# MK70F12 register map
Vendor: Freescale Semiconductor, Inc.; Series: Kinetis_K; File version: 1.6
CPU: CM4 r0p1, little endian, no MPU, FPU, VTOR, 4 interrupt priority bits
Registers are 32-bit, read-write, reset 0x0 unless marked. A register's access mark holds for its fields unless they carry their own. Offsets are from the block's base; [hi:lo] are bit positions; {n}, {i} and the like mark numbered series; 'fields as' and 'values as' point back to an identical list; <NAME> marks a mode.

## ENET — Ethernet MAC-NET Core
Base 0x400C0000; register names take the prefix ENET_
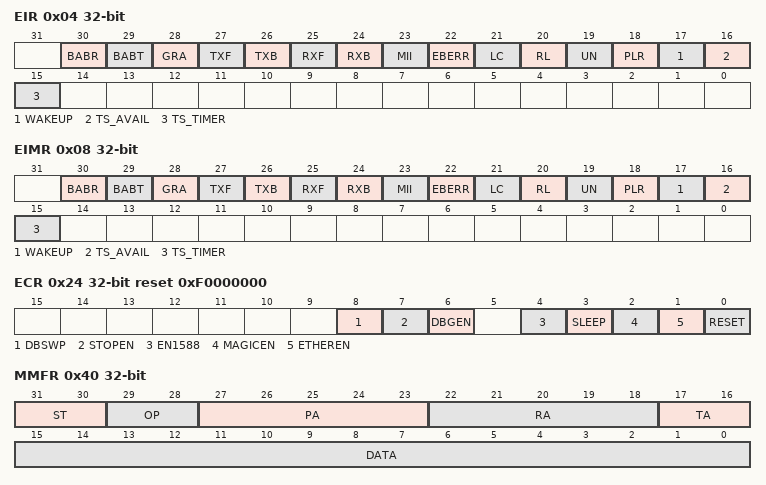
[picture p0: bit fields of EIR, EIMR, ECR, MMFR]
0x04 EIR — Interrupt Event Register
  [30] BABR — Babbling Receive Error
  [29] BABT — Babbling Transmit Error
  [28] GRA — Graceful Stop Complete
  [27] TXF — Transmit Frame Interrupt
  [26] TXB — Transmit Buffer Interrupt
  [25] RXF — Receive Frame Interrupt
  [24] RXB — Receive Buffer Interrupt.
  [23] MII — MII Interrupt.
  [22] EBERR — Ethernet Bus Error
  [21] LC — Late Collision
  [20] RL — Collision Retry Limit.
  [19] UN — Transmit FIFO underrun
  [18] PLR — Payload receive error
  [17] WAKEUP — Node wake-up request indication
  [16] TS_AVAIL — Transmit timestamp available
  [15] TS_TIMER — Timestamp timer
0x08 EIMR — Interrupt Mask Register
  [30] BABR — BABR interrupt mask
    0=The corresponding interrupt source is masked; 1=The corresponding interrupt source is not masked
  [29] BABT — BABT interrupt mask
    values as BABR
  [28] GRA — GRA interrupt mask
    values as BABR
  [27] TXF — TXF interrupt mask
    values as BABR
  [26] TXB — TXB interrupt mask
    values as BABR
  [25] RXF — RXF interrupt mask
  [24] RXB — RXB interrupt mask
  [23] MII — MII interrupt mask
  [22] EBERR — EBERR interrupt mask
  [21] LC — LC interrupt mask
  [20] RL — RL interrupt mask
  [19] UN — UN interrupt mask
  [18] PLR — PLR interrupt mask
  [17] WAKEUP — WAKEUP interrupt mask
  [16] TS_AVAIL — TS_AVAIL interrupt mask
  [15] TS_TIMER — TS_TIMER interrupt mask
0x10 RDAR — Receive Descriptor Active Register
  [24] RDAR — Receive descriptor active
0x14 TDAR — Transmit Descriptor Active Register
  [24] TDAR — Transmit descriptor active
0x24 ECR reset 0xF0000000 — Ethernet Control Register
  [8] DBSWP — Descriptor Byte Swapping Enable
    0=The buffer descriptor bytes are not swapped to support big-endian devices; 1=The buffer descriptor bytes are swapped to support little-endian devices
  [7] STOPEN — STOPEN Signal Control
  [6] DBGEN — Debug enable
    0=MAC continues operation in debug mode; 1=MAC enters hardware freeze mode when the processor is in debug mode
  [4] EN1588 — EN1588 enable
    0=Legacy FEC buffer descriptors and functions enabled; 1=Enhanced frame time-stamping functions enabled
  [3] SLEEP — Sleep mode enable
    0=Normal operating mode; 1=Sleep mode
  [2] MAGICEN — Magic packet detection enable
    0=Magic detection logic disabled; 1=The MAC core detects magic packets and asserts EIR[WAKEUP] when a frame is detected
  [1] ETHEREN — Ethernet enable
    0=Reception immediately stops and transmission stops after a bad CRC is appended to any currently transmitted frame; 1=MAC is enabled, and reception and transmission are possible
  [0] RESET — Ethernet MAC reset
0x40 MMFR — MII Management Frame Register
  [31:30] ST — Start of frame delimiter
  [29:28] OP — Operation code
    0=Write frame operation, but not MII compliant; 1=Write frame operation for a valid MII management frame; 2=Read frame operation for a valid MII management frame; 3=Read frame operation, but not MII compliant
  [27:23] PA — PHY address
  [22:18] RA — Register address
  [17:16] TA — Turn around
  [15:0] DATA — Management frame data
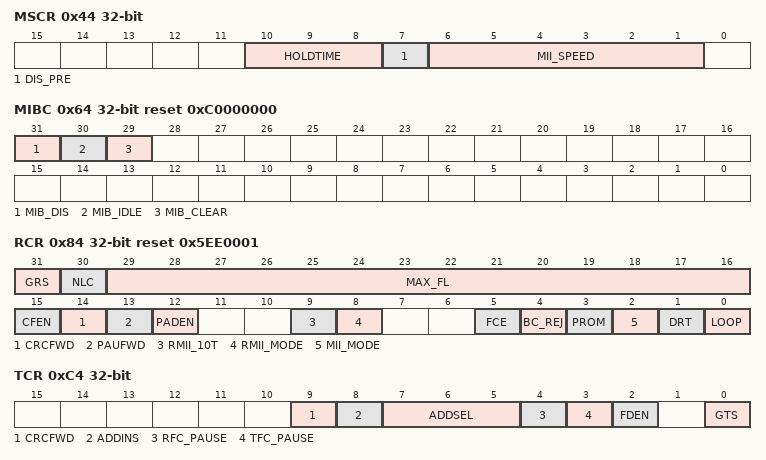
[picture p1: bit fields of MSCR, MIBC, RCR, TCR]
0x44 MSCR — MII Speed Control Register
  [10:8] HOLDTIME — Holdtime on MDIO output
    0=1 internal module clock cycle; 1=2 internal module clock cycles; 2=3 internal module clock cycles; 7=8 internal module clock cycles
  [7] DIS_PRE — Disable preamble
    0=Preamble enabled; 1=Preamble (32 ones) is not prepended to the MII management frame
  [6:1] MII_SPEED
0x64 MIBC reset 0xC0000000 — MIB Control Register
  [31] MIB_DIS — Disable MIB logic
  [30] MIB_IDLE ro
  [29] MIB_CLEAR
0x84 RCR reset 0x5EE0001 — Receive Control Register
  [31] GRS ro — Graceful receive stopped
  [30] NLC — Payload length check disable
    0=The payload length check is disabled; 1=The core checks the frame's payload length with the frame length/type field. Errors are indicated in the EIR[PLC] bit.
  [29:16] MAX_FL — Maximum frame length
  [15] CFEN — MAC control frame enable
    0=MAC control frames with any opcode other than 0x0001 are accepted and forwarded to the client interface; 1=MAC control frames with any opcode other than 0x0001 (pause frame) are silently discarded
  [14] CRCFWD — Terminate/forward received CRC
    0=The CRC field of received frames is transmitted to the user application; 1=The CRC field is stripped from the frame
  [13] PAUFWD — Terminate/forward pause frames.
    0=Pause frames are terminated and discarded in the MAC; 1=Pause frames are forwarded to the user application
  [12] PADEN — Enable frame padding remove on receive
    0=No padding is removed on receive by the MAC; 1=Padding is removed from received frames
  [9] RMII_10T — Enables 10-Mbps mode of the RMII .
    0=100 Mbps operation; 1=10 Mbps operation
  [8] RMII_MODE — RMII mode enable
    0=MAC configured for MII mode; 1=MAC configured for RMII operation
  [5] FCE — Flow control enable
  [4] BC_REJ — Broadcast frame reject
  [3] PROM — Promiscuous mode. All frames are accepted regardless of address matching.
    0=Disabled; 1=Enabled
  [2] MII_MODE — Media independent interface mode
    1=MII or RMII mode, as indicated by the RMII_MODE bit
  [1] DRT — Disable receive on transmit
    0=Receive path operates independently of transmit (use for full duplex or to monitor transmit activity in half duplex mode); 1=Disable reception of frames while transmitting (normally used for half duplex mode)
  [0] LOOP — Internal loopback
    0=Loopback disabled; 1=Transmitted frames are looped back internal to the device and transmit MII output signals are not asserted. DRT must be cleared. .
0xC4 TCR — Transmit Control Register
  [9] CRCFWD — Forward frame from application with CRC
    0=TxBD[TC] controls whether the frame has a CRC from the application; 1=The transmitter does not append any CRC to transmitted frames as it is expecting a frame with CRC from the application
  [8] ADDINS — Set MAC address on transmit
    0=The source MAC address is not modified by the MAC; 1=The MAC overwrites the source MAC address with the programmed MAC address according to ADDSEL
  [7:5] ADDSEL — Source MAC address select on transmit
    0=Node MAC address programmed on PADDR1/2 registers
  [4] RFC_PAUSE ro — Receive frame control pause
  [3] TFC_PAUSE — Transmit frame control pause
    0=No PAUSE frame transmitted; 1=The MAC stops transmission of data frames after the current transmission is complete
  [2] FDEN — Full duplex enable
  [0] GTS — Graceful transmit stop
0xE4 PALR — Physical Address Lower Register
  [31:0] PADDR1 — Pause address
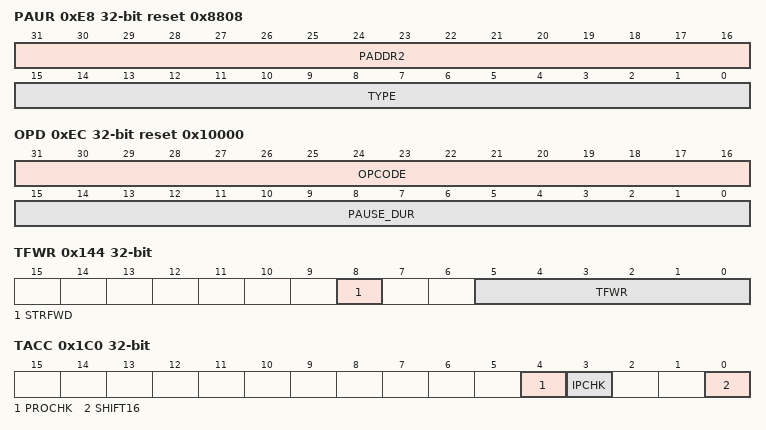
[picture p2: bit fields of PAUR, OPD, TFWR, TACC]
0xE8 PAUR reset 0x8808 — Physical Address Upper Register
  [31:16] PADDR2 — Bytes 4 (bits 31:24) and 5 (bits 23:16) of the 6-byte individual address used for exact match, and the source address field in PAUSE frames
  [15:0] TYPE ro — Type field in PAUSE frames.
0xEC OPD reset 0x10000 — Opcode/Pause Duration Register
  [31:16] OPCODE ro — Opcode field in PAUSE frames
  [15:0] PAUSE_DUR — Pause duration
0x118 IAUR — Descriptor Individual Upper Address Register
  [31:0] IADDR1 — The upper 32 bits of the 64-bit hash table used in the address recognition process for receive frames with a unicast address
0x11C IALR — Descriptor Individual Lower Address Register
  [31:0] IADDR2 — The lower 32 bits of the 64-bit hash table used in the address recognition process for receive frames with a unicast address
0x120 GAUR — Descriptor Group Upper Address Register
  [31:0] GADDR1 — Contains the upper 32 bits of the 64-bit hash table used in the address recognition process for receive frames with a multicast address
0x124 GALR — Descriptor Group Lower Address Register
  [31:0] GADDR2 — Contains the lower 32 bits of the 64-bit hash table used in the address recognition process for receive frames with a multicast address
0x144 TFWR — Transmit FIFO Watermark Register
  [8] STRFWD — Store and forward enable
    0=Disabled, the transmission start threshold is programmed in TFWR; 1=Enabled
  [5:0] TFWR — Transmit FIFO write
    0=64 bytes written; 1=64 bytes written; 2=128 bytes written; 3=192 bytes written; 63=4032 bytes written
0x180 RDSR — Receive Descriptor Ring Start Register
  [31:3] R_DES_START — Pointer to the start of the receive buffer descriptor queue.
0x184 TDSR — Transmit Buffer Descriptor Ring Start Register
  [31:3] X_DES_START — Pointer to the start of the transmit buffer descriptor queue.
0x188 MRBR — Maximum Receive Buffer Size Register
  [13:4] R_BUF_SIZE — Receive buffer size in bytes.
0x190 RSFL — Receive FIFO Section Full Threshold
  [7:0] RX_SECTION_FULL — Value of receive FIFO section full threshold
0x194 RSEM — Receive FIFO Section Empty Threshold
  [7:0] RX_SECTION_EMPTY — Value of the receive FIFO section empty threshold
0x198 RAEM reset 0x4 — Receive FIFO Almost Empty Threshold
  [7:0] RX_ALMOST_EMPTY — Value of the receive FIFO almost empty threshold
0x19C RAFL reset 0x4 — Receive FIFO Almost Full Threshold
  [7:0] RX_ALMOST_FULL — Value of the receive FIFO almost full threshold
0x1A0 TSEM — Transmit FIFO Section Empty Threshold
  [7:0] TX_SECTION_EMPTY — Value of the transmit FIFO section empty threshold
0x1A4 TAEM reset 0x4 — Transmit FIFO Almost Empty Threshold
  [7:0] TX_ALMOST_EMPTY — Value of transmit FIFO almost empty threshold
0x1A8 TAFL reset 0x8 — Transmit FIFO Almost Full Threshold
  [7:0] TX_ALMOST_FULL — Value of the transmit FIFO almost full threshold
0x1AC TIPG reset 0xC — Transmit Inter-Packet Gap
  [4:0] IPG — Transmit inter-packet gap
0x1B0 FTRL reset 0x7FF — Frame Truncation Length
  [13:0] TRUNC_FL — Frame truncation length
0x1C0 TACC — Transmit Accelerator Function Configuration
  [4] PROCHK — Enables insertion of protocol checksum.
    0=Checksum not inserted; 1=If an IP frame with a known protocol is transmitted, the checksum is inserted automatically into the frame. The checksum field must be cleared. The other frames are not modified.
  [3] IPCHK — Enables insertion of IP header checksum.
    0=Checksum is not inserted; 1=If an IP frame is transmitted, the checksum is inserted automatically. The IP header checksum field must be cleared. If a non-IP frame is transmitted the frame is not modified.
  [0] SHIFT16 — TX FIFO shift-16
    0=Disabled; 1=Indicates to the transmit data FIFO, that the written frames contain two additional octets before the frame data. This means the actual frame starts at bit 16 of the first word written into the FIFO. This function allows putting the frame payload on a 32-bit boundary in memory, as the 14-byte Ethernet header is extended to a 16-byte header.
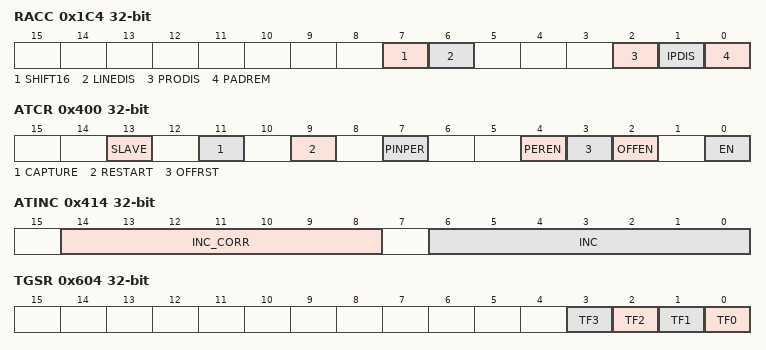
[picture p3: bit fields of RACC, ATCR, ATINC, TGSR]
0x1C4 RACC — Receive Accelerator Function Configuration
  [7] SHIFT16 — RX FIFO shift-16
    0=Disabled; 1=Instructs the MAC to write two additional bytes in front of each frame received into the RX FIFO
  [6] LINEDIS — Enable discard of frames with MAC layer errors
    0=Frames with errors are not discarded; 1=Any frame received with a CRC, length, or PHY error is automatically discarded and not forwarded to the user application interface
  [2] PRODIS — Enable discard of frames with wrong protocol checksum
    0=Frames with wrong checksum are not discarded; 1=If a TCP/IP, UDP/IP, or ICMP/IP frame is received that has a wrong TCP, UDP, or ICMP checksum, the frame is discarded. Discarding is only available when the RX FIFO operates in store and forward mode (RSFL cleared).
  [1] IPDIS — Enable discard of frames with wrong IPv4 header checksum.
    0=Frames with wrong IPv4 header checksum are not discarded; 1=If an IPv4 frame is received with a mismatching header checksum, the frame is discarded. IPv6 has no header checksum and is not affected by this setting. Discarding is only available when the RX FIFO operates in store and forward mode (RSFL cleared).
  [0] PADREM — Enable padding removal for short IP frames.
    0=Padding not removed; 1=Any bytes following the IP payload section of the frame are removed from the frame
0x200 RMON_T_DROP reset not defined — Count of frames not counted correctly (RMON_T_DROP). NOTE: Counter not implemented (read 0 always) as not applicable.
0x204 RMON_T_PACKETS — RMON Tx packet count (RMON_T_PACKETS)
  [15:0] TXPKTS ro — Packet count
0x208 RMON_T_BC_PKT — RMON Tx Broadcast Packets (RMON_T_BC_PKT)
  [15:0] TXPKTS ro — Broadcast packets
0x20C RMON_T_MC_PKT — RMON Tx Multicast Packets (RMON_T_MC_PKT)
  [15:0] TXPKTS ro — Multicast packets
0x210 RMON_T_CRC_ALIGN — RMON Tx Packets w CRC/Align error (RMON_T_CRC_ALIGN)
  [15:0] TXPKTS ro — Packets with CRC/align error
0x214 RMON_T_UNDERSIZE — RMON Tx Packets < 64 bytes, good CRC (RMON_T_UNDERSIZE)
  [15:0] TXPKTS ro — Packet count
0x218 RMON_T_OVERSIZE — RMON Tx Packets > MAX_FL bytes, good CRC (RMON_T_OVERSIZE)
  [15:0] TXPKTS ro — Packet count
0x21C RMON_T_FRAG — RMON Tx Packets < 64 bytes, bad CRC (RMON_T_FRAG)
  [15:0] TXPKTS ro — Packet count
0x220 RMON_T_JAB — RMON Tx Packets > MAX_FL bytes, bad CRC (RMON_T_JAB)
  [15:0] TXPKTS ro — Packet count
0x224 RMON_T_COL — RMON Tx collision count (RMON_T_COL)
  [15:0] TXPKTS ro — Packet count
0x228 RMON_T_P64 — RMON Tx 64 byte packets (RMON_T_P64)
  [15:0] TXPKTS ro — Packet count
0x22C RMON_T_P65TO127 — RMON Tx 65 to 127 byte packets (RMON_T_P65TO127)
  [15:0] TXPKTS ro — Packet count
0x230 RMON_T_P128TO255 — RMON Tx 128 to 255 byte packets (RMON_T_P128TO255)
  [15:0] TXPKTS ro — Packet count
0x234 RMON_T_P256TO511 — RMON Tx 256 to 511 byte packets (RMON_T_P256TO511)
  [15:0] TXPKTS ro — Packet count
0x238 RMON_T_P512TO1023 — RMON Tx 512 to 1023 byte packets (RMON_T_P512TO1023)
  [15:0] TXPKTS ro — Packet count
0x23C RMON_T_P1024TO2047 — RMON Tx 1024 to 2047 byte packets (RMON_T_P1024TO2047)
  [15:0] TXPKTS ro — Packet count
0x240 RMON_T_P_GTE2048 — RMON Tx packets w > 2048 bytes (RMON_T_P_GTE2048)
  [15:0] TXPKTS ro — Packet count
0x244 RMON_T_OCTETS ro — RMON Tx Octets (RMON_T_OCTETS)
  [31:0] TXOCTS — Octet count
0x248 IEEE_T_DROP reset not defined — Count of frames not counted correctly (IEEE_T_DROP). NOTE: Counter not implemented (read 0 always) as not applicable.
0x24C IEEE_T_FRAME_OK — Frames Transmitted OK (IEEE_T_FRAME_OK)
  [15:0] COUNT ro — Frame count
0x250 IEEE_T_1COL — Frames Transmitted with Single Collision (IEEE_T_1COL)
  [15:0] COUNT ro — Frame count
0x254 IEEE_T_MCOL — Frames Transmitted with Multiple Collisions (IEEE_T_MCOL)
  [15:0] COUNT ro — Frame count
0x258 IEEE_T_DEF — Frames Transmitted after Deferral Delay (IEEE_T_DEF)
  [15:0] COUNT ro — Frame count
0x25C IEEE_T_LCOL — Frames Transmitted with Late Collision (IEEE_T_LCOL)
  [15:0] COUNT ro — Frame count
0x260 IEEE_T_EXCOL — Frames Transmitted with Excessive Collisions (IEEE_T_EXCOL)
  [15:0] COUNT ro — Frame count
0x264 IEEE_T_MACERR — Frames Transmitted with Tx FIFO Underrun (IEEE_T_MACERR)
  [15:0] COUNT ro — Frame count
0x268 IEEE_T_CSERR — Frames Transmitted with Carrier Sense Error (IEEE_T_CSERR)
  [15:0] COUNT ro — Frame count
0x26C IEEE_T_SQE reset not defined — Frames Transmitted with SQE Error (IEEE_T_SQE). NOTE: Counter not implemented (read 0 always) as no SQE information is available.
0x270 IEEE_T_FDXFC — Flow Control Pause frames transmitted (IEEE_T_FDXFC)
  [15:0] COUNT ro — Frame count
0x274 IEEE_T_OCTETS_OK ro — Octet count for Frames Transmitted w/o Error (IEEE_T_OCTETS_OK). NOTE: Counts total octets (includes header and FCS fields).
  [31:0] COUNT — Octet count
0x284 RMON_R_PACKETS — RMON Rx packet count (RMON_R_PACKETS)
  [15:0] COUNT ro — Packet count
0x288 RMON_R_BC_PKT — RMON Rx Broadcast Packets (RMON_R_BC_PKT)
  [15:0] COUNT ro — Packet count
0x28C RMON_R_MC_PKT — RMON Rx Multicast Packets (RMON_R_MC_PKT)
  [15:0] COUNT ro — Packet count
0x290 RMON_R_CRC_ALIGN — RMON Rx Packets w CRC/Align error (RMON_R_CRC_ALIGN)
  [15:0] COUNT ro — Packet count
0x294 RMON_R_UNDERSIZE — RMON Rx Packets < 64 bytes, good CRC (RMON_R_UNDERSIZE)
  [15:0] COUNT ro — Packet count
0x298 RMON_R_OVERSIZE — RMON Rx Packets > MAX_FL bytes, good CRC (RMON_R_OVERSIZE)
  [15:0] COUNT ro — Packet count
0x29C RMON_R_FRAG — RMON Rx Packets < 64 bytes, bad CRC (RMON_R_FRAG)
  [15:0] COUNT ro — Packet count
0x2A0 RMON_R_JAB — RMON Rx Packets > MAX_FL bytes, bad CRC (RMON_R_JAB)
  [15:0] COUNT ro — Packet count
0x2A4 RMON_R_RESVD_0 reset not defined — Reserved (RMON_R_RESVD_0)
0x2A8 RMON_R_P64 — RMON Rx 64 byte packets (RMON_R_P64)
  [15:0] COUNT ro — Packet count
0x2AC RMON_R_P65TO127 — RMON Rx 65 to 127 byte packets (RMON_R_P65TO127)
  [15:0] COUNT ro — Packet count
0x2B0 RMON_R_P128TO255 — RMON Rx 128 to 255 byte packets (RMON_R_P128TO255)
  [15:0] COUNT ro — Packet count
0x2B4 RMON_R_P256TO511 — RMON Rx 256 to 511 byte packets (RMON_R_P256TO511)
  [15:0] COUNT ro — Packet count
0x2B8 RMON_R_P512TO1023 — RMON Rx 512 to 1023 byte packets (RMON_R_P512TO1023)
  [15:0] COUNT ro — Packet count
0x2BC RMON_R_P1024TO2047 — RMON Rx 1024 to 2047 byte packets (RMON_R_P1024TO2047)
  [15:0] COUNT ro — Packet count
0x2C0 RMON_R_P_GTE2048 — RMON Rx packets w > 2048 bytes (RMON_R_P_GTE2048)
  [15:0] COUNT ro — Packet count
0x2C4 RMON_R_OCTETS ro — RMON Rx Octets (RMON_R_OCTETS)
  [31:0] COUNT — Octet count
0x2C8 IEEE_R_DROP — Count of frames not counted correctly (IEEE_R_DROP). NOTE: Counter increments if a frame with valid/missing SFD character is detected and has been dropped. None of the other counters increments if this counter increments.
  [15:0] COUNT ro — Frame count
0x2CC IEEE_R_FRAME_OK — Frames Received OK (IEEE_R_FRAME_OK)
  [15:0] COUNT ro — Frame count
0x2D0 IEEE_R_CRC — Frames Received with CRC Error (IEEE_R_CRC)
  [15:0] COUNT ro — Frame count
0x2D4 IEEE_R_ALIGN — Frames Received with Alignment Error (IEEE_R_ALIGN)
  [15:0] COUNT ro — Frame count
0x2D8 IEEE_R_MACERR — Receive Fifo Overflow count (IEEE_R_MACERR)
  [15:0] COUNT ro
0x2DC IEEE_R_FDXFC — Flow Control Pause frames received (IEEE_R_FDXFC)
  [15:0] COUNT ro — Pause frame count
0x2E0 IEEE_R_OCTETS_OK ro — Octet count for Frames Rcvd w/o Error (IEEE_R_OCTETS_OK). Counts total octets (includes header and FCS fields).
  [31:0] COUNT — Octet count
0x400 ATCR — Timer Control Register
  [13] SLAVE — Enable timer slave mode
    0=The timer is active and all configuration bits in this register are relevant; 1=The internal timer is disabled and the externally provided timer value is used. All other bits, except CAPTURE, in this register have no effect. CAPTURE can still be used to capture the current timer value.
  [11] CAPTURE — Capture timer value
    0=No effect; 1=The current time is captured and can be read from the ATVR register
  [9] RESTART — Reset timer
  [7] PINPER — Enables event signal output assertion on period event
    0=Disable; 1=Enable
  [4] PEREN — Enable periodical event
    0=Disable; 1=A period event interrupt can be generated (EIR[TS_TIMER]) and the event signal output is asserted when the timer wraps around according to the periodic setting ATPER. Set the timer period value before setting this bit. Not all devices contain the event signal output. See the Chip Configuration details.
  [3] OFFRST — Reset timer on offset event
    0=The timer is not affected and no action occurs (besides clearing OFFEN) when the offset is reached; 1=If OFFEN is set, the timer resets to zero when the offset setting is reached. The offset event does not cause a timer interrupt.
  [2] OFFEN — Enable one-shot offset event
    0=Disable; 1=The timer can be reset to zero when the given offset time is reached (offset event). The bit is cleared when the offset event is reached, so no further event occurs until the bit is set again. Set the timer offset value before setting this bit.
  [0] EN — Enable timer
    0=The timer stops at the current value; 1=The timer starts incrementing
0x404 ATVR — Timer Value Register
  [31:0] ATIME — A write sets the timer
0x408 ATOFF — Timer Offset Register
  [31:0] OFFSET — Offset value for one-shot event generation
0x40C ATPER reset 0x3B9ACA00 — Timer Period Register
  [31:0] PERIOD — Value for generating periodic events
0x410 ATCOR — Timer Correction Register
  [30:0] COR — Correction counter wrap-around value
0x414 ATINC — Time-Stamping Clock Period Register
  [14:8] INC_CORR — Correction increment value
  [6:0] INC — Clock period of the timestamping clock (ts_clk) in nanoseconds
0x418 ATSTMP — Timestamp of Last Transmitted Frame
  [31:0] TIMESTAMP — Timestamp of the last frame transmitted by the core that had TxBD[TS] set
0x604 TGSR — Timer Global Status Register
  [n] TF{n} (n=0..3) — Copy of Timer Flag for channel {n}
    0=Timer Flag for Channel {n} is clear; 1=Timer Flag for Channel {n} is set
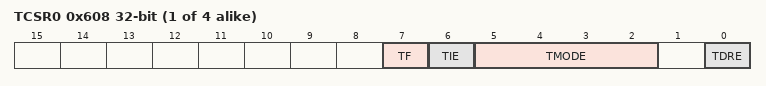
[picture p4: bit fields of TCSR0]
{0x608+8i} TCSR{i} (i=0..3) — Timer Control Status Register
  [7] TF — Timer Flag
    0=Input Capture or Output Compare has not occurred; 1=Input Capture or Output Compare has occurred
  [6] TIE — Timer interrupt enable
    0=Interrupt is disabled; 1=Interrupt is enabled
  [5:2] TMODE — Timer Mode
    0=Timer Channel is disabled; 1=Timer Channel is configured for Input Capture on rising edge; 2=Timer Channel is configured for Input Capture on falling edge; 3=Timer Channel is configured for Input Capture on both edges; 4=Timer Channel is configured for Output Compare - software only; 5=Timer Channel is configured for Output Compare - toggle output on compare; 6=Timer Channel is configured for Output Compare - clear output on compare; 7=Timer Channel is configured for Output Compare - set output on compare; 10=Timer Channel is configured for Output Compare - clear output on compare, set output on overflow; 0b10x1=Timer Channel is configured for Output Compare - set output on compare, clear output on overflow; 14=Timer Channel is configured for Output Compare - pulse output low on compare for one 1588 clock cycle; 15=Timer Channel is configured for Output Compare - pulse output high on compare for one 1588 clock cycle
  [0] TDRE — Timer DMA Request Enable
    0=DMA request is disabled; 1=DMA request is enabled
{0x60C+8i} TCCR{i} (i=0..3) — Timer Compare Capture Register
  [31:0] TCC — Timer Capture Compare
